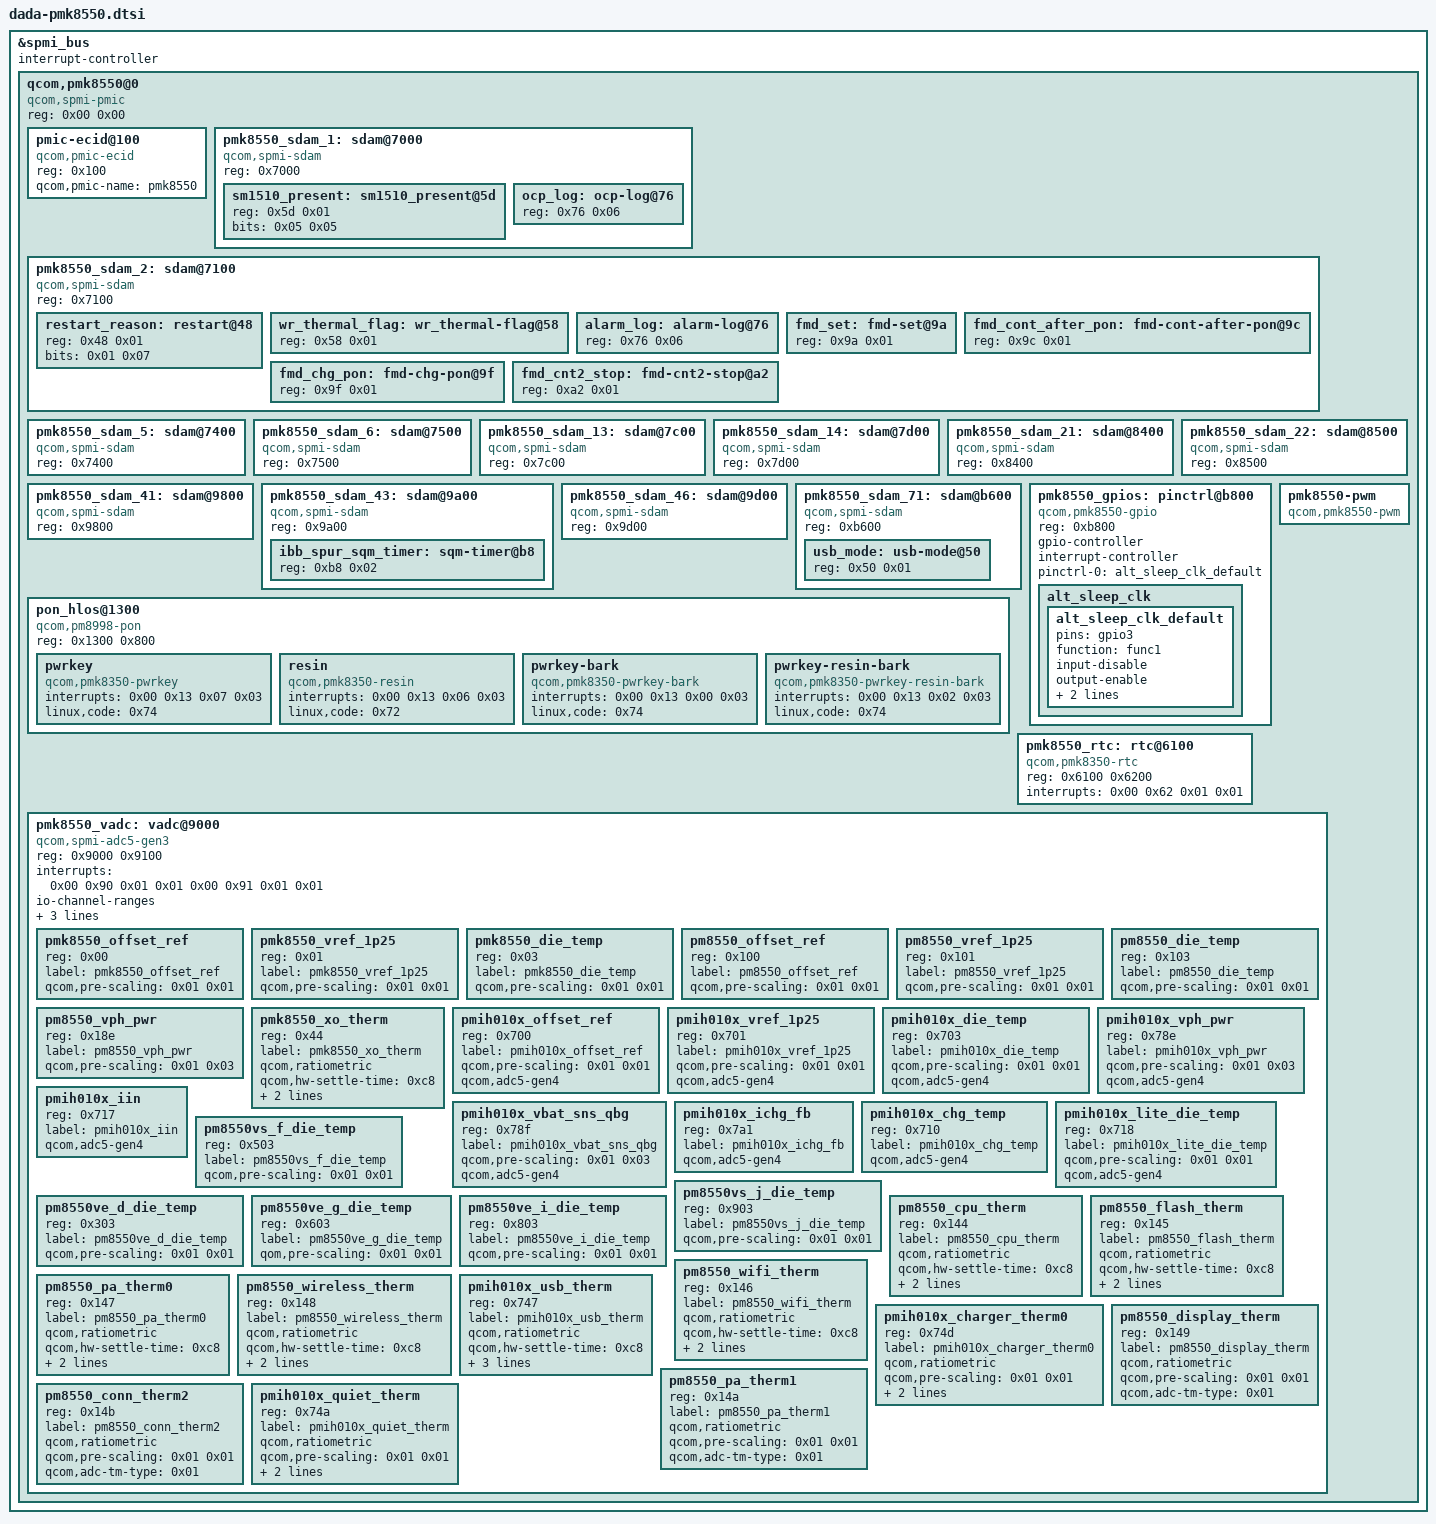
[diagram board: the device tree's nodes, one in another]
// SPDX-License-Identifier: BSD-3-Clause
/*
 * Copyright (c) 2023-2024 Qualcomm Innovation Center, Inc. All rights reserved.
 * Copyright (c) 2025 The LineageOS Project
 */

&spmi_bus {
	#address-cells = <0x02>;
	#size-cells = <0x00>;
	interrupt-controller;
	#interrupt-cells = <0x04>;

	qcom,pmk8550@0 {
		compatible = "qcom,spmi-pmic";
		reg = <0x00 0x00>;
		#address-cells = <0x01>;
		#size-cells = <0x00>;

		pmic-ecid@100 {
			compatible = "qcom,pmic-ecid";
			reg = <0x100>;
			qcom,pmic-name = "pmk8550";
		};

		pmk8550_sdam_1: sdam@7000 {
			compatible = "qcom,spmi-sdam";
			reg = <0x7000>;
			#address-cells = <0x01>;
			#size-cells = <0x01>;

			sm1510_present: sm1510_present@5d {
				reg = <0x5d 0x01>;
				bits = <0x05 0x05>;
			};

			ocp_log: ocp-log@76 {
				reg = <0x76 0x06>;
			};
		};

		pmk8550_sdam_2: sdam@7100 {
			compatible = "qcom,spmi-sdam";
			reg = <0x7100>;
			#address-cells = <0x01>;
			#size-cells = <0x01>;

			restart_reason: restart@48 {
				reg = <0x48 0x01>;
				bits = <0x01 0x07>;
			};

			wr_thermal_flag: wr_thermal-flag@58 {
				reg = <0x58 0x01>;
			};

			alarm_log: alarm-log@76 {
				reg = <0x76 0x06>;
			};

			fmd_set: fmd-set@9a {
				reg = <0x9a 0x01>;
			};

			fmd_cont_after_pon: fmd-cont-after-pon@9c {
				reg = <0x9c 0x01>;
			};

			fmd_chg_pon: fmd-chg-pon@9f {
				reg = <0x9f 0x01>;
			};

			fmd_cnt2_stop: fmd-cnt2-stop@a2 {
				reg = <0xa2 0x01>;
			};
		};

		pmk8550_sdam_5: sdam@7400 {
			compatible = "qcom,spmi-sdam";
			reg = <0x7400>;
		};

		pmk8550_sdam_6: sdam@7500 {
			compatible = "qcom,spmi-sdam";
			reg = <0x7500>;
		};

		pmk8550_sdam_13: sdam@7c00 {
			compatible = "qcom,spmi-sdam";
			reg = <0x7c00>;
		};

		pmk8550_sdam_14: sdam@7d00 {
			compatible = "qcom,spmi-sdam";
			reg = <0x7d00>;
		};

		pmk8550_sdam_21: sdam@8400 {
			compatible = "qcom,spmi-sdam";
			reg = <0x8400>;
		};

		pmk8550_sdam_22: sdam@8500 {
			compatible = "qcom,spmi-sdam";
			reg = <0x8500>;
		};

		pmk8550_sdam_41: sdam@9800 {
			compatible = "qcom,spmi-sdam";
			reg = <0x9800>;
		};

		pmk8550_sdam_43: sdam@9a00 {
			compatible = "qcom,spmi-sdam";
			reg = <0x9a00>;
			#address-cells = <0x01>;
			#size-cells = <0x01>;

			ibb_spur_sqm_timer: sqm-timer@b8 {
				reg = <0xb8 0x02>;
			};
		};

		pmk8550_sdam_46: sdam@9d00 {
			compatible = "qcom,spmi-sdam";
			reg = <0x9d00>;
		};

		pmk8550_sdam_71: sdam@b600 {
			compatible = "qcom,spmi-sdam";
			reg = <0xb600>;

			usb_mode: usb-mode@50 {
				reg = <0x50 0x01>;
			};
		};

		pon_hlos@1300 {
			compatible = "qcom,pm8998-pon";
			reg = <0x1300 0x800>;
			reg-names = "pon_hlos", "pon_pbs";

			pwrkey {
				compatible = "qcom,pmk8350-pwrkey";
				interrupts = <0x00 0x13 0x07 0x03>;
				linux,code = <0x74>;
			};

			resin {
				compatible = "qcom,pmk8350-resin";
				interrupts = <0x00 0x13 0x06 0x03>;
				linux,code = <0x72>;
			};

			pwrkey-bark {
				compatible = "qcom,pmk8350-pwrkey-bark";
				interrupts = <0x00 0x13 0x00 0x03>;
				linux,code = <0x74>;
			};

			pwrkey-resin-bark {
				compatible = "qcom,pmk8350-pwrkey-resin-bark";
				interrupts = <0x00 0x13 0x02 0x03>;
				linux,code = <0x74>;
			};
		};

		pmk8550_gpios: pinctrl@b800 {
			compatible = "qcom,pmk8550-gpio";
			reg = <0xb800>;
			gpio-controller;
			#gpio-cells = <0x02>;
			interrupt-controller;
			#interrupt-cells = <0x02>;
			pinctrl-0 = <&alt_sleep_clk_default>;
			pinctrl-names = "default";

			alt_sleep_clk {

				alt_sleep_clk_default: alt_sleep_clk_default {
					pins = "gpio3";
					function = "func1";
					input-disable;
					output-enable;
					bias-disable;
					power-source = <0x00>;
				};
			};
		};

		pmk8550_rtc: rtc@6100 {
			compatible = "qcom,pmk8350-rtc";
			reg = <0x6100 0x6200>;
			reg-names = "rtc", "alarm";
			interrupts = <0x00 0x62 0x01 0x01>;
		};

		pmk8550-pwm {
			compatible = "qcom,pmk8550-pwm";
			#address-cells = <0x01>;
			#size-cells = <0x00>;
			#pwm-cells = <0x02>;
		};

		pmk8550_vadc: vadc@9000 {
			compatible = "qcom,spmi-adc5-gen3";
			reg = <0x9000 0x9100>;
			#address-cells = <0x01>;
			#size-cells = <0x00>;
			interrupt-names = "adc-sdam0", "adc-sdam1";
			interrupts = <0x00 0x90 0x01 0x01 0x00 0x91 0x01 0x01>;
			#thermal-sensor-cells = <0x01>;
			#io-channel-cells = <0x01>;
			io-channel-ranges;
			pinctrl-names = "default";
			pinctrl-0 = <&pa_therm1_default &conn_therm2_default &quiet_therm_default &display_therm_default>;

			pmk8550_offset_ref {
				reg = <0x00>;
				label = "pmk8550_offset_ref";
				qcom,pre-scaling = <0x01 0x01>;
			};

			pmk8550_vref_1p25 {
				reg = <0x01>;
				label = "pmk8550_vref_1p25";
				qcom,pre-scaling = <0x01 0x01>;
			};

			pmk8550_die_temp {
				reg = <0x03>;
				label = "pmk8550_die_temp";
				qcom,pre-scaling = <0x01 0x01>;
			};

			pm8550_offset_ref {
				reg = <0x100>;
				label = "pm8550_offset_ref";
				qcom,pre-scaling = <0x01 0x01>;
			};

			pm8550_vref_1p25 {
				reg = <0x101>;
				label = "pm8550_vref_1p25";
				qcom,pre-scaling = <0x01 0x01>;
			};

			pm8550_die_temp {
				reg = <0x103>;
				label = "pm8550_die_temp";
				qcom,pre-scaling = <0x01 0x01>;
			};

			pm8550_vph_pwr {
				reg = <0x18e>;
				label = "pm8550_vph_pwr";
				qcom,pre-scaling = <0x01 0x03>;
			};

			pmk8550_xo_therm {
				reg = <0x44>;
				label = "pmk8550_xo_therm";
				qcom,ratiometric;
				qcom,hw-settle-time = <0xc8>;
				qcom,pre-scaling = <0x01 0x01>;
				qcom,adc-tm-type = <0x01>;
			};

			pmih010x_offset_ref {
				reg = <0x700>;
				label = "pmih010x_offset_ref";
				qcom,pre-scaling = <0x01 0x01>;
				qcom,adc5-gen4;
			};

			pmih010x_vref_1p25 {
				reg = <0x701>;
				label = "pmih010x_vref_1p25";
				qcom,pre-scaling = <0x01 0x01>;
				qcom,adc5-gen4;
			};

			pmih010x_die_temp {
				reg = <0x703>;
				label = "pmih010x_die_temp";
				qcom,pre-scaling = <0x01 0x01>;
				qcom,adc5-gen4;
			};

			pmih010x_vph_pwr {
				reg = <0x78e>;
				label = "pmih010x_vph_pwr";
				qcom,pre-scaling = <0x01 0x03>;
				qcom,adc5-gen4;
			};

			pmih010x_vbat_sns_qbg {
				reg = <0x78f>;
				label = "pmih010x_vbat_sns_qbg";
				qcom,pre-scaling = <0x01 0x03>;
				qcom,adc5-gen4;
			};

			pmih010x_iin {
				reg = <0x717>;
				label = "pmih010x_iin";
				qcom,adc5-gen4;
			};

			pmih010x_ichg_fb {
				reg = <0x7a1>;
				label = "pmih010x_ichg_fb";
				qcom,adc5-gen4;
			};

			pmih010x_chg_temp {
				reg = <0x710>;
				label = "pmih010x_chg_temp";
				qcom,adc5-gen4;
			};

			pmih010x_lite_die_temp {
				reg = <0x718>;
				label = "pmih010x_lite_die_temp";
				qcom,pre-scaling = <0x01 0x01>;
				qcom,adc5-gen4;
			};

			pm8550vs_f_die_temp {
				reg = <0x503>;
				label = "pm8550vs_f_die_temp";
				qcom,pre-scaling = <0x01 0x01>;
			};

			pm8550vs_j_die_temp {
				reg = <0x903>;
				label = "pm8550vs_j_die_temp";
				qcom,pre-scaling = <0x01 0x01>;
			};

			pm8550ve_d_die_temp {
				reg = <0x303>;
				label = "pm8550ve_d_die_temp";
				qcom,pre-scaling = <0x01 0x01>;
			};

			pm8550ve_g_die_temp {
				reg = <0x603>;
				label = "pm8550ve_g_die_temp";
				qom,pre-scaling = <0x01 0x01>;
			};

			pm8550ve_i_die_temp {
				reg = <0x803>;
				label = "pm8550ve_i_die_temp";
				qcom,pre-scaling = <0x01 0x01>;
			};

			pm8550_cpu_therm {
				reg = <0x144>;
				label = "pm8550_cpu_therm";
				qcom,ratiometric;
				qcom,hw-settle-time = <0xc8>;
				qcom,pre-scaling = <0x01 0x01>;
				qcom,adc-tm-type = <0x01>;
			};

			pm8550_flash_therm {
				reg = <0x145>;
				label = "pm8550_flash_therm";
				qcom,ratiometric;
				qcom,hw-settle-time = <0xc8>;
				qcom,pre-scaling = <0x01 0x01>;
				qcom,adc-tm-type = <0x01>;
			};

			pm8550_wifi_therm {
				reg = <0x146>;
				label = "pm8550_wifi_therm";
				qcom,ratiometric;
				qcom,hw-settle-time = <0xc8>;
				qcom,pre-scaling = <0x01 0x01>;
				qcom,adc-tm-type = <0x01>;
			};

			pm8550_pa_therm0 {
				reg = <0x147>;
				label = "pm8550_pa_therm0";
				qcom,ratiometric;
				qcom,hw-settle-time = <0xc8>;
				qcom,pre-scaling = <0x01 0x01>;
				qcom,adc-tm-type = <0x01>;
			};

			pm8550_wireless_therm {
				reg = <0x148>;
				label = "pm8550_wireless_therm";
				qcom,ratiometric;
				qcom,hw-settle-time = <0xc8>;
				qcom,pre-scaling = <0x01 0x01>;
				qcom,adc-tm-type = <0x01>;
			};

			pmih010x_usb_therm {
				reg = <0x747>;
				label = "pmih010x_usb_therm";
				qcom,ratiometric;
				qcom,hw-settle-time = <0xc8>;
				qcom,pre-scaling = <0x01 0x01>;
				qcom,adc-tm-type = <0x01>;
				qcom,adc5-gen4;
			};

			pmih010x_charger_therm0 {
				reg = <0x74d>;
				label = "pmih010x_charger_therm0";
				qcom,ratiometric;
				qcom,pre-scaling = <0x01 0x01>;
				qcom,adc-tm-type = <0x01>;
				qcom,adc5-gen4;
			};

			pm8550_display_therm {
				reg = <0x149>;
				label = "pm8550_display_therm";
				qcom,ratiometric;
				qcom,pre-scaling = <0x01 0x01>;
				qcom,adc-tm-type = <0x01>;
			};

			pm8550_pa_therm1 {
				reg = <0x14a>;
				label = "pm8550_pa_therm1";
				qcom,ratiometric;
				qcom,pre-scaling = <0x01 0x01>;
				qcom,adc-tm-type = <0x01>;
			};

			pm8550_conn_therm2 {
				reg = <0x14b>;
				label = "pm8550_conn_therm2";
				qcom,ratiometric;
				qcom,pre-scaling = <0x01 0x01>;
				qcom,adc-tm-type = <0x01>;
			};

			pmih010x_quiet_therm {
				reg = <0x74a>;
				label = "pmih010x_quiet_therm";
				qcom,ratiometric;
				qcom,pre-scaling = <0x01 0x01>;
				qcom,adc-tm-type = <0x01>;
				qcom,adc5-gen4;
			};
		};
	};
};
